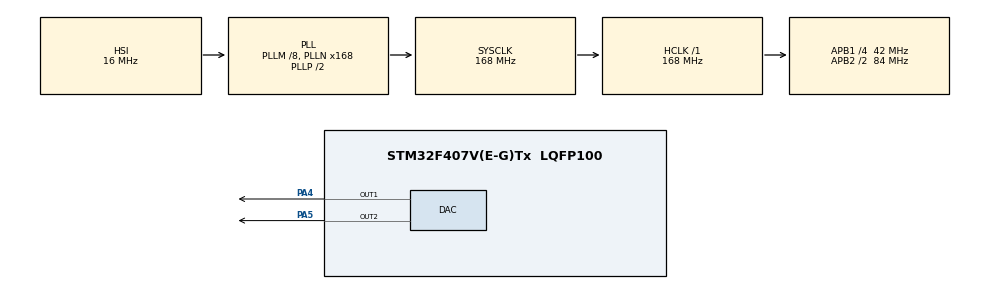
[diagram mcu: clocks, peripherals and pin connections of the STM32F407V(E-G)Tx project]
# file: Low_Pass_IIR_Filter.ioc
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Mcu.Family=STM32F4
Mcu.Name=STM32F407V(E-G)Tx
Mcu.Package=LQFP100
NVIC.PriorityGroup=NVIC_PRIORITYGROUP_4
PA13.Mode=Serial_Wire
PA13.Signal=SYS_JTMS-SWDIO
PA14.Mode=Serial_Wire
PA14.Signal=SYS_JTCK-SWCLK
PA4.Signal=COMP_DAC1_group
PA5.Signal=COMP_DAC2_group
PH0-OSC_IN.Mode=HSE-External-Oscillator
PH0-OSC_IN.Signal=RCC_OSC_IN
PH1-OSC_OUT.Mode=HSE-External-Oscillator
PH1-OSC_OUT.Signal=RCC_OSC_OUT
ProjectManager.HeapSize=0x200
ProjectManager.StackSize=0x400
ProjectManager.TargetToolchain=STM32CubeIDE
RCC.48MHZClocksFreq_Value=84000000
RCC.AHBFreq_Value=168000000
RCC.APB1CLKDivider=RCC_HCLK_DIV4
RCC.APB1Freq_Value=42000000
RCC.APB1TimFreq_Value=84000000
RCC.APB2CLKDivider=RCC_HCLK_DIV2
RCC.APB2Freq_Value=84000000
RCC.APB2TimFreq_Value=168000000
RCC.CortexFreq_Value=168000000
RCC.HCLKFreq_Value=168000000
RCC.HSE_VALUE=8000000
RCC.HSI_VALUE=16000000
RCC.LSE_VALUE=32768
RCC.PLLM=8
RCC.PLLN=168
RCC.SYSCLKFreq_VALUE=168000000
RCC.SYSCLKSource=RCC_SYSCLKSOURCE_PLLCLK
RCC.VCOOutputFreq_Value=336000000
SH.COMP_DAC1_group.0=DAC_OUT1,DAC_OUT1
SH.COMP_DAC2_group.0=DAC_OUT2,DAC_OUT2
board=custom

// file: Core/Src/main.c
/* USER CODE BEGIN Header */
/**
  ******************************************************************************
  * @file           : main.c
  * @brief          : Main program body
  ******************************************************************************
  * @attention
  *
  * Copyright (c) 2025 STMicroelectronics.
  * All rights reserved.
  *
  * This software is licensed under terms that can be found in the LICENSE file
  * in the root directory of this software component.
  * If no LICENSE file comes with this software, it is provided AS-IS.
  *
  ******************************************************************************
  */
/*
 *                                 ***NOT***
 * Bu kod, 1024 örnekten oluşan gürültülü (temel sinüs + yüksek frekanslı bileşen) bir test sinyali üretir ve STM32 DAC üzerinden çıkış verir.
 * Üretilen sinyal, 5. dereceden bir IIR low-pass filtreden geçirilmektedir.
 */
/* USER CODE END Header */
#include "main.h"
#include <math.h>
/* USER CODE BEGIN Includes */
#define NCoef 5
/* USER CODE END Includes */

DAC_HandleTypeDef hdac;

/* USER CODE BEGIN PV */

float TestSignal[1024];    //Filtreye girecek ham test sinyalidir.
float OutputSignal[1024];  //IIR filtreden çıkmış filtrelenmiş sinyalidir.
uint32_t i;

/* USER CODE END PV */

void SystemClock_Config(void);
static void MX_GPIO_Init(void);
static void MX_DAC_Init(void);
/* USER CODE BEGIN PFP */

float iir(float NewSample);

/* USER CODE END PFP */

int main(void)
{

  /* MCU Configuration--------------------------------------------------------*/

  /* Reset of all peripherals, Initializes the Flash interface and the Systick. */
  HAL_Init();

  /* Configure the system clock */
  SystemClock_Config();

  /* Initialize all configured peripherals */
  MX_GPIO_Init();
  MX_DAC_Init();
  /* USER CODE BEGIN 2 */

  HAL_DAC_Start(&hdac, DAC_CHANNEL_1);   //Filtre çıkışını vermek için.
  HAL_DAC_Start(&hdac, DAC_CHANNEL_2);   //Ham giriş sinyalini vereceksin.
  //Osiloskopta CH1 = filtreli, CH2 = ham görünecektir.

  for (i=0; i<1024;i++)
  {
	  TestSignal[i] = (float)(400*sin(2*3.14*10*i*0.001))+512;  //Test sinyalini oluşturuyoruz. 10 Hz sinüs dalgası, Genlik: 400, Offset: +512
	  //+512 ekleme sebebim sinüs negatif olmasın diye ortalayıp yukarı kaydırıyorum.

	  //TestSignal[i] = (float)((400*sin(2*3.14*10*i*0.001)) + (100*sin(2*3.14*400*i*0.001))) + 512;
  }

  /* USER CODE END 2 */

  /* Infinite loop */
  while (1)
  {

    /* USER CODE BEGIN 3 */
	  for (i=100; i<900;i++)
	  {
		  OutputSignal[i] = iir(TestSignal[i]);
		  HAL_DAC_SetValue(&hdac, DAC_CHANNEL_1, DAC_ALIGN_12B_R, (int)OutputSignal[i]); //Filtreli
		  HAL_DAC_SetValue(&hdac, DAC_CHANNEL_2, DAC_ALIGN_12B_R, (int)TestSignal[i]);   //Ham

		  HAL_Delay(0);
	  }
//100'den başlama sebebi filtrenin ilk örneklerinde transient(başlangıç tepkisi) kısmı var (x ve y geçmişi sıfırdan başlıyor).
//Kenar örnekleriyle uğraşmamak için ortadan alıyorsun.

  }
  /* USER CODE END 3 */
}

void SystemClock_Config(void)
{
  RCC_OscInitTypeDef RCC_OscInitStruct = {0};
  RCC_ClkInitTypeDef RCC_ClkInitStruct = {0};

  /** Configure the main internal regulator output voltage
  */
  __HAL_RCC_PWR_CLK_ENABLE();
  __HAL_PWR_VOLTAGESCALING_CONFIG(PWR_REGULATOR_VOLTAGE_SCALE1);

  /** Initializes the RCC Oscillators according to the specified parameters
  * in the RCC_OscInitTypeDef structure.
  */
  RCC_OscInitStruct.OscillatorType = RCC_OSCILLATORTYPE_HSI;
  RCC_OscInitStruct.HSIState = RCC_HSI_ON;
  RCC_OscInitStruct.HSICalibrationValue = RCC_HSICALIBRATION_DEFAULT;
  RCC_OscInitStruct.PLL.PLLState = RCC_PLL_ON;
  RCC_OscInitStruct.PLL.PLLSource = RCC_PLLSOURCE_HSI;
  RCC_OscInitStruct.PLL.PLLM = 8;
  RCC_OscInitStruct.PLL.PLLN = 168;
  RCC_OscInitStruct.PLL.PLLP = RCC_PLLP_DIV2;
  RCC_OscInitStruct.PLL.PLLQ = 4;
  if (HAL_RCC_OscConfig(&RCC_OscInitStruct) != HAL_OK)
  {
    Error_Handler();
  }

  /** Initializes the CPU, AHB and APB buses clocks
  */
  RCC_ClkInitStruct.ClockType = RCC_CLOCKTYPE_HCLK|RCC_CLOCKTYPE_SYSCLK
                              |RCC_CLOCKTYPE_PCLK1|RCC_CLOCKTYPE_PCLK2;
  RCC_ClkInitStruct.SYSCLKSource = RCC_SYSCLKSOURCE_PLLCLK;
  RCC_ClkInitStruct.AHBCLKDivider = RCC_SYSCLK_DIV1;
  RCC_ClkInitStruct.APB1CLKDivider = RCC_HCLK_DIV4;
  RCC_ClkInitStruct.APB2CLKDivider = RCC_HCLK_DIV2;

  if (HAL_RCC_ClockConfig(&RCC_ClkInitStruct, FLASH_LATENCY_5) != HAL_OK)
  {
    Error_Handler();
  }
}

static void MX_DAC_Init(void)
{

  DAC_ChannelConfTypeDef sConfig = {0};

  /** DAC Initialization
  */
  hdac.Instance = DAC;
  if (HAL_DAC_Init(&hdac) != HAL_OK)
  {
    Error_Handler();
  }

  /** DAC channel OUT1 config
  */
  sConfig.DAC_Trigger = DAC_TRIGGER_NONE;
  sConfig.DAC_OutputBuffer = DAC_OUTPUTBUFFER_ENABLE;
  if (HAL_DAC_ConfigChannel(&hdac, &sConfig, DAC_CHANNEL_1) != HAL_OK)
  {
    Error_Handler();
  }

  /** DAC channel OUT2 config
  */
  if (HAL_DAC_ConfigChannel(&hdac, &sConfig, DAC_CHANNEL_2) != HAL_OK)
  {
    Error_Handler();
  }

}

static void MX_GPIO_Init(void)
{

  /* GPIO Ports Clock Enable */
  __HAL_RCC_GPIOH_CLK_ENABLE();
  __HAL_RCC_GPIOA_CLK_ENABLE();

}

/* USER CODE BEGIN 4 */

float iir(float NewSample) {
    float ACoef[NCoef+1] = {
        0.00006248961583259117,
        0.00031244807916295581,
        0.00062489615832591163,
        0.00062489615832591163,
        0.00031244807916295581,
        0.00006248961583259117
    };

    float BCoef[NCoef+1] = {
        1.00000000000000000000,
        -3.98454311961233690000,
        6.43486709027586820000,
        -5.25361517035226730000,
        2.16513290972413230000,
        -0.35992824506355597000
    };

    static float y[NCoef+1]; //output samples
    static float x[NCoef+1]; //input samples
    int n;

    //shift the old samples
    for(n=NCoef; n>0; n--) {
       x[n] = x[n-1];
       y[n] = y[n-1];
    }

    //Calculate the new output
    x[0] = NewSample;
    y[0] = ACoef[0] * x[0];
    for(n=1; n<=NCoef; n++)
        y[0] += ACoef[n] * x[n] - BCoef[n] * y[n];

    return y[0];
}

/* USER CODE END 4 */

void Error_Handler(void)
{
  __disable_irq();
  while (1)
  {
  }
}
